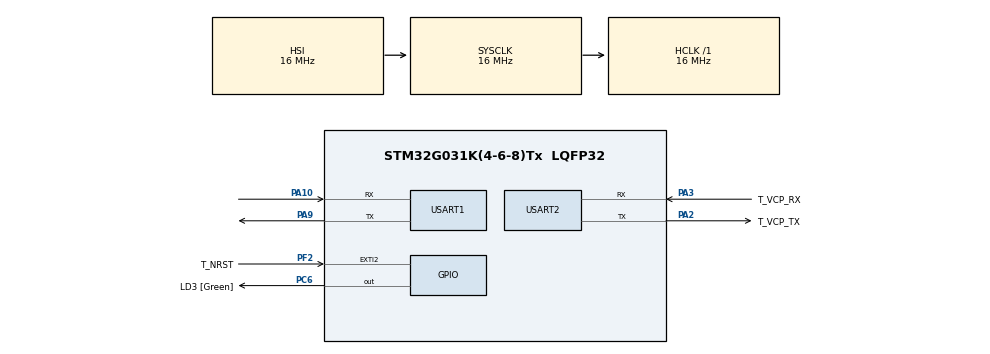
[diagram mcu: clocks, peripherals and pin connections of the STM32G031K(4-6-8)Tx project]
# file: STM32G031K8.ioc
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Mcu.Family=STM32G0
Mcu.Name=STM32G031K(4-6-8)Tx
Mcu.Package=LQFP32
NVIC.TIM16_IRQn=true\:0\:0\:false\:false\:true\:true\:true
PA10.Mode=Asynchronous
PA10.Signal=USART1_RX
PA13.GPIO_Label=T_JTMS
PA13.Mode=Serial_Wire
PA13.Signal=SYS_SWDIO
PA14-BOOT0.GPIO_Label=T_JTCK
PA14-BOOT0.Mode=Serial_Wire
PA14-BOOT0.Signal=SYS_SWCLK
PA2.GPIO_Label=T_VCP_TX
PA2.GPIO_PuPd=GPIO_PULLUP
PA2.Mode=Asynchronous
PA2.Signal=USART2_TX
PA3.GPIO_Label=T_VCP_RX
PA3.GPIO_PuPd=GPIO_PULLUP
PA3.Mode=Asynchronous
PA3.Signal=USART2_RX
PA9.Mode=Asynchronous
PA9.Signal=USART1_TX
PC14-OSC32_IN\ (PC14).Mode=LSE-External-Oscillator
PC14-OSC32_IN\ (PC14).Signal=RCC_OSC32_IN
PC15-OSC32_OUT\ (PC15).Mode=LSE-External-Oscillator
PC15-OSC32_OUT\ (PC15).Signal=RCC_OSC32_OUT
PC6.GPIO_Label=LD3 [Green]
PC6.Signal=GPIO_Output
PF2\ -\ NRST.GPIO_Label=T_NRST
PF2\ -\ NRST.Signal=GPXTI2
ProjectManager.HeapSize=0x200
ProjectManager.StackSize=0x400
ProjectManager.TargetToolchain=STM32CubeIDE
RCC.AHBFreq_Value=16000000
RCC.CortexFreq_Value=16000000
RCC.EXTERNAL_CLOCK_VALUE=12288000
RCC.HCLKFreq_Value=16000000
RCC.HSE_VALUE=8000000
RCC.HSI_VALUE=16000000
RCC.SYSCLKFreq_VALUE=16000000
RCC.VCOOutputFreq_Value=128000000
TIM16.Period=10000 - 1
TIM16.Prescaler=1600 - 1
USART1.VirtualMode-Asynchronous=VM_ASYNC
USART2.VirtualMode-Asynchronous=VM_ASYNC
USART2.WordLength=WORDLENGTH_7B
VP_TIM16_VS_ClockSourceINT.Mode=Enable_Timer
board=NUCLEO-G031K8

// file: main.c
/* USER CODE BEGIN Header */
/**
  ******************************************************************************
  * @file           : main.c
  * @brief          : Main program body
  ******************************************************************************
  * @attention
  *
  * <h2><center>&copy; Copyright (c) 2020 STMicroelectronics.
  * All rights reserved.</center></h2>
  *
  * This software component is licensed by ST under BSD 3-Clause license,
  * the "License"; You may not use this file except in compliance with the
  * License. You may obtain a copy of the License at:
  *                        opensource.org/licenses/BSD-3-Clause
  *
  ******************************************************************************
  */
/* USER CODE END Header */
#include "main.h"
#include "tim.h"
#include "usart.h"
#include "gpio.h"

/* USER CODE BEGIN Includes */
#include <stdio.h>
/* USER CODE END Includes */

/* USER CODE BEGIN PV */

TIM_HandleTypeDef htim16;
UART_HandleTypeDef huart1;
UART_HandleTypeDef huart2;

/* USER CODE END PV */

void SystemClock_Config(void);

int main(void)
{
  /* USER CODE BEGIN 1 */

  char uart_buf[50];
  int uart_buf_len;
  uint16_t timer_val;

  /* USER CODE END 1 */

  /* MCU Configuration--------------------------------------------------------*/

  /* Reset of all peripherals, Initializes the Flash interface and the Systick. */
  HAL_Init();

  /* Configure the system clock */
  SystemClock_Config();

  /* Initialize all configured peripherals */
  MX_GPIO_Init();
  MX_USART2_UART_Init();
  MX_TIM16_Init();
  MX_USART1_UART_Init();
  /* USER CODE BEGIN 2 */

  // Say something
  uart_buf_len = sprintf(uart_buf, "Timer Test\r\n");
  HAL_UART_Transmit(&huart1, (uint8_t *)uart_buf, uart_buf_len, 100);
//  HAL_UART_Transmit(&huart2, (uint8_t *)uart_buf, uart_buf_len, 100);

  // Start timer
  HAL_TIM_Base_Start_IT(&htim16);

  // Get current time (microseconds)
  timer_val = __HAL_TIM_GET_COUNTER(&htim16);

  /* USER CODE END 2 */

  /* Infinite loop */
  while (1)
  {

  }
}

void SystemClock_Config(void)
{
  RCC_OscInitTypeDef RCC_OscInitStruct = {0};
  RCC_ClkInitTypeDef RCC_ClkInitStruct = {0};
  RCC_PeriphCLKInitTypeDef PeriphClkInit = {0};

  /** Configure the main internal regulator output voltage
  */
  HAL_PWREx_ControlVoltageScaling(PWR_REGULATOR_VOLTAGE_SCALE1);
  /** Initializes the RCC Oscillators according to the specified parameters
  * in the RCC_OscInitTypeDef structure.
  */
  RCC_OscInitStruct.OscillatorType = RCC_OSCILLATORTYPE_HSI;
  RCC_OscInitStruct.HSIState = RCC_HSI_ON;
  RCC_OscInitStruct.HSIDiv = RCC_HSI_DIV1;
  RCC_OscInitStruct.HSICalibrationValue = RCC_HSICALIBRATION_DEFAULT;
  RCC_OscInitStruct.PLL.PLLState = RCC_PLL_NONE;
  if (HAL_RCC_OscConfig(&RCC_OscInitStruct) != HAL_OK)
  {
    Error_Handler();
  }
  /** Initializes the CPU, AHB and APB buses clocks
  */
  RCC_ClkInitStruct.ClockType = RCC_CLOCKTYPE_HCLK|RCC_CLOCKTYPE_SYSCLK
                              |RCC_CLOCKTYPE_PCLK1;
  RCC_ClkInitStruct.SYSCLKSource = RCC_SYSCLKSOURCE_HSI;
  RCC_ClkInitStruct.AHBCLKDivider = RCC_SYSCLK_DIV1;
  RCC_ClkInitStruct.APB1CLKDivider = RCC_HCLK_DIV1;

  if (HAL_RCC_ClockConfig(&RCC_ClkInitStruct, FLASH_LATENCY_0) != HAL_OK)
  {
    Error_Handler();
  }
  /** Initializes the peripherals clocks
  */
  PeriphClkInit.PeriphClockSelection = RCC_PERIPHCLK_USART1;
  PeriphClkInit.Usart1ClockSelection = RCC_USART1CLKSOURCE_PCLK1;
  if (HAL_RCCEx_PeriphCLKConfig(&PeriphClkInit) != HAL_OK)
  {
    Error_Handler();
  }
}

/* USER CODE BEGIN 4 */
// Callback: timer has rolled over
void HAL_TIM_PeriodElapsedCallback(TIM_HandleTypeDef *htim)
{
  // Check which version of the timer triggered this callback and toggle LED
  if (htim == &htim16 )
  {
    HAL_GPIO_TogglePin(LD3_GPIO_Port, LD3_Pin);
  }
}
/* USER CODE END 4 */

void Error_Handler(void)
{
}

/************************ (C) COPYRIGHT STMicroelectronics *****END OF FILE****/
